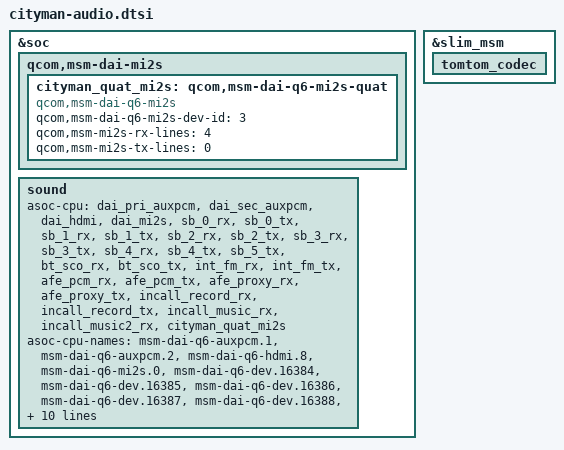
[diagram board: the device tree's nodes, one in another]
/* SPDX-License-Identifier: GPL-2.0-only */
/* Cityman's TAS2553 backend requires its own Q6 Quaternary MI2S endpoint. */

&soc {
	qcom,msm-dai-mi2s {
		cityman_quat_mi2s: qcom,msm-dai-q6-mi2s-quat {
			compatible = "qcom,msm-dai-q6-mi2s";
			qcom,msm-dai-q6-mi2s-dev-id = <3>;
			qcom,msm-mi2s-rx-lines = <4>; /* SD2: TAS2553 input */
			qcom,msm-mi2s-tx-lines = <0>;
		};
	};

	sound {
		/* Keep the inherited name/phandle pairs, adding the speaker DAI.
		 * The platform driver's OF device name differs from its DAI name;
		 * the machine driver therefore needs this explicit phandle map.
		 */
		asoc-cpu = <&dai_pri_auxpcm>, <&dai_sec_auxpcm>, <&dai_hdmi>, <&dai_mi2s>,
				<&sb_0_rx>, <&sb_0_tx>, <&sb_1_rx>, <&sb_1_tx>,
				<&sb_2_rx>, <&sb_2_tx>, <&sb_3_rx>, <&sb_3_tx>,
				<&sb_4_rx>, <&sb_4_tx>, <&sb_5_tx>, <&bt_sco_rx>,
				<&bt_sco_tx>, <&int_fm_rx>, <&int_fm_tx>, <&afe_pcm_rx>,
				<&afe_pcm_tx>, <&afe_proxy_rx>, <&afe_proxy_tx>,
				<&incall_record_rx>, <&incall_record_tx>, <&incall_music_rx>,
				<&incall_music2_rx>,
				<&cityman_quat_mi2s>;
		asoc-cpu-names = "msm-dai-q6-auxpcm.1", "msm-dai-q6-auxpcm.2",
				"msm-dai-q6-hdmi.8", "msm-dai-q6-mi2s.0",
				"msm-dai-q6-dev.16384", "msm-dai-q6-dev.16385",
				"msm-dai-q6-dev.16386", "msm-dai-q6-dev.16387",
				"msm-dai-q6-dev.16388", "msm-dai-q6-dev.16389",
				"msm-dai-q6-dev.16390", "msm-dai-q6-dev.16391",
				"msm-dai-q6-dev.16392", "msm-dai-q6-dev.16393",
				"msm-dai-q6-dev.16395", "msm-dai-q6-dev.12288",
				"msm-dai-q6-dev.12289", "msm-dai-q6-dev.12292",
				"msm-dai-q6-dev.12293", "msm-dai-q6-dev.224",
				"msm-dai-q6-dev.225", "msm-dai-q6-dev.241",
				"msm-dai-q6-dev.240", "msm-dai-q6-dev.32771",
				"msm-dai-q6-dev.32772", "msm-dai-q6-dev.32773",
				"msm-dai-q6-dev.32770",
				"msm-dai-q6-mi2s.3";
	};
};

/*
 * Cityman has no ultrasound emitter and no speaker on the WCD9330's own
 * class-D driver: the loudspeaker is the TAS2553 above. Once the card
 * registers, the machine driver would otherwise claim PMI8994 GPIO 1 and
 * the codec would switch the PMI8994 5 V boost on demand for an output
 * that is not connected.
 */
&soc {
	sound {
		/delete-property/ qcom,ext-ult-spk-amp-gpio;
	};
};

&slim_msm {
	tomtom_codec {
		/delete-property/ cdc-vdd-spkdrv-supply;
		/delete-property/ qcom,cdc-vdd-spkdrv-voltage;
		/delete-property/ qcom,cdc-vdd-spkdrv-current;
		/delete-property/ cdc-vdd-spkdrv-2-supply;
		/delete-property/ qcom,cdc-vdd-spkdrv-2-voltage;
		/delete-property/ qcom,cdc-vdd-spkdrv-2-current;
		/delete-property/ qcom,cdc-on-demand-supplies;
	};
};
